# R7FA2A1AB register map
Vendor: Renesas; Series: RA2; File version: 1.1
CPU: CM23 r1p0, little endian, MPU, no FPU, VTOR, 2 interrupt priority bits
Registers are 8-bit, read-write, reset 0x0 unless marked. A register's access mark holds for its fields unless they carry their own. Offsets are from the block's base; [hi:lo] are bit positions; {n}, {i} and the like mark numbered series.

## SYSTEM — System Control
Base 0x4001E000
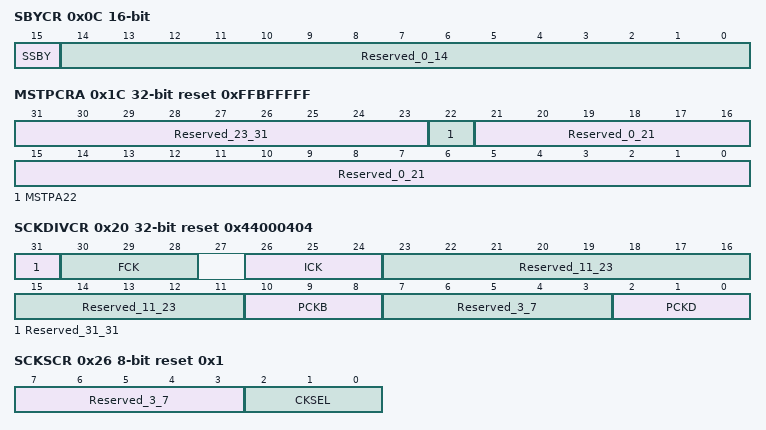
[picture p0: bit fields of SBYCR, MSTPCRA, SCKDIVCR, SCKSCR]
0x0C SBYCR 16-bit — Standby Control Register
  [15] SSBY — Software Standby
  [14:0] Reserved_0_14 — These bits are read as 000000000000000. The write value should be 000000000000000.
0x1C MSTPCRA 32-bit reset 0xFFBFFFFF — Module Stop Control Register A
  [31:23] Reserved_23_31 — These bits are read as 111111111. The write value should be 111111111.
  [22] MSTPA22 — Data Transfer Controller Module Stop
  [21:0] Reserved_0_21 — These bits are read as 1111111111111111111111. The write value should be 1111111111111111111111.
0x20 SCKDIVCR 32-bit reset 0x44000404 — System Clock Division Control Register
  [31] Reserved_31_31 — This bit is read as 0. The write value should be 0.
  [30:28] FCK — Flash IF Clock (FCLK) Select
  [26:24] ICK — System Clock (ICLK) Select
  [23:11] Reserved_11_23 — These bits are read as 0000000000000. The write value should be 0000000000000.
  [10:8] PCKB — Peripheral Module Clock B (PCLKB) Select
  [7:3] Reserved_3_7 — These bits are read as 00000. The write value should be 00000.
  [2:0] PCKD — Peripheral Module Clock D (PCLKD) Select
0x26 SCKSCR reset 0x1 — System Clock Source Control Register
  [7:3] Reserved_3_7 — These bits are read as 00000. The write value should be 00000.
  [2:0] CKSEL — Clock Source Select
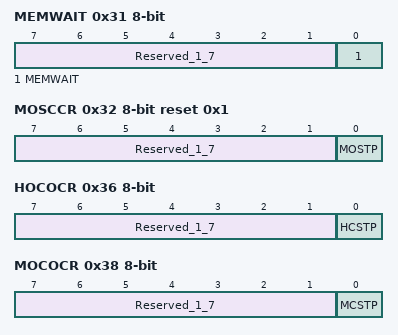
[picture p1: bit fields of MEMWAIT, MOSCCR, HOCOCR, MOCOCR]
0x31 MEMWAIT — Memory Wait Cycle Control Register
  [7:1] Reserved_1_7 — These bits are read as 0000000. The write value should be 0000000.
  [0] MEMWAIT — Memory Wait Cycle Select
0x32 MOSCCR reset 0x1 — Main Clock Oscillator Control Register
  [7:1] Reserved_1_7 — These bits are read as 0000000. The write value should be 0000000.
  [0] MOSTP — Main Clock Oscillator Stop
0x36 HOCOCR (reset mask 0xFE) — High,Speed On,Chip Oscillator Control Register
  [7:1] Reserved_1_7 — These bits are read as 0000000. The write value should be 0000000.
  [0] HCSTP — HOCO Stop
0x38 MOCOCR — Middle,Speed On,Chip Oscillator Control Register
  [7:1] Reserved_1_7 — These bits are read as 0000000. The write value should be 0000000.
  [0] MCSTP — MOCO Stop
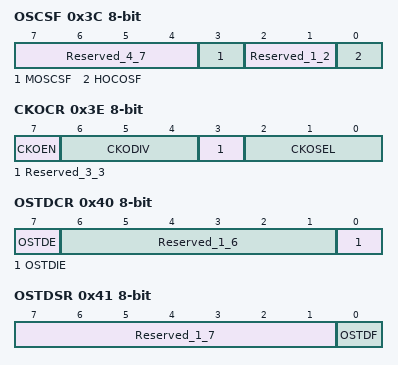
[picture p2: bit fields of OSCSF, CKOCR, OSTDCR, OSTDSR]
0x3C OSCSF ro (reset mask 0xFE) — Oscillation Stabilization Flag Register
  [7:4] Reserved_4_7 — These bits are read as 0000.
  [3] MOSCSF — Main Clock Oscillation Stabilization Flag
  [2:1] Reserved_1_2 — These bits are read as 00.
  [0] HOCOSF — HOCO Clock Oscillation Stabilization FlagNOTE: The HOCOSF bit value after a reset is 1 when the OFS1.HOCOEN bit is 0. It is 0 when the OFS1.HOCOEN bit is 1.
0x3E CKOCR — Clock Out Control Register
  [7] CKOEN — Clock out enable
  [6:4] CKODIV — Clock out input frequency Division Select
  [3] Reserved_3_3 — This bit is read as 0. The write value should be 0.
  [2:0] CKOSEL — Clock out source select
0x40 OSTDCR — Oscillation Stop Detection Control Register
  [7] OSTDE — Oscillation Stop Detection Function Enable
  [6:1] Reserved_1_6 — These bits are read as 000000. The write value should be 000000.
  [0] OSTDIE — Oscillation Stop Detection Interrupt Enable
0x41 OSTDSR — Oscillation Stop Detection Status Register
  [7:1] Reserved_1_7 — These bits are read as 0000000. The write value should be 0000000.
  [0] OSTDF write-0-clears read-modifies — Oscillation Stop Detection Flag
0x61 MOCOUTCR — MOCO User Trimming Control Register
  [7:0] MOCOUTRM — MOCO User Trimming 1000_0000 : -128 1000_0001 : -127 1000_0010 : -126 . . . 1111_1111 : -1 0000_0000 : Center Code 0000_0001 : +1 . . . 0111_1101 : +125 0111_1110 : +126 0111_1111 : +127These bits are added to original MOCO trimming bits
0x62 HOCOUTCR — HOCO User Trimming Control Register
  [7:0] HOCOUTRM — HOCO User Trimming 1000_0000 : -128 1000_0001 : -127 1000_0010 : -126 . . . 1111_1111 : -1 0000_0000 : Center Code 0000_0001 : +1 . . . 0111_1101 : +125 0111_1110 : +126 0111_1111 : +127These bits are added to original HOCO trimming bits
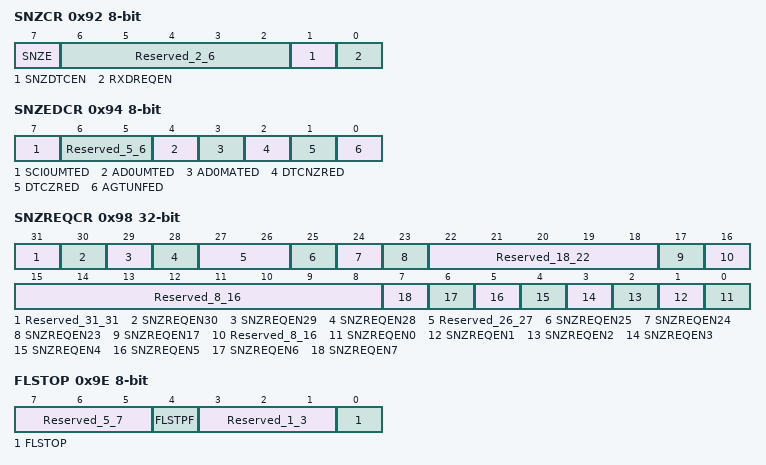
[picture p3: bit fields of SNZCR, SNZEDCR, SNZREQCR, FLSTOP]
0x92 SNZCR — Snooze Control Register
  [7] SNZE — Snooze Mode Enable
  [6:2] Reserved_2_6 — These bits are read as 00000. The write value should be 00000.
  [1] SNZDTCEN — DTC Enable in Snooze Mode
  [0] RXDREQEN — RXD0 Snooze Request Enable NOTE: Do not set to 1 other than in asynchronous mode.
0x94 SNZEDCR — Snooze End Control Register
  [7] SCI0UMTED — SCI0 address unmatch Snooze End EnableNote: Do not set to 1 other than in asynchronous mode.
  [6:5] Reserved_5_6 — These bits are read as 00. The write value should be 00.
  [4] AD0UMTED — AD compare mismatch 0 Snooze End Enable
  [3] AD0MATED — AD compare match 0 Snooze End Enable
  [2] DTCNZRED — Not Last DTC transmission completion Snooze End Enable
  [1] DTCZRED — Last DTC transmission completion Snooze End Enable
  [0] AGTUNFED — AGT1 underflow Snooze End Enable
0x98 SNZREQCR 32-bit — Snooze Request Control Register
  [31] Reserved_31_31 — This bit is read as 0. The write value should be 0.
  [30] SNZREQEN30 — Snooze Request Enable 30Enable AGT1 compare match B snooze request
  [29] SNZREQEN29 — Snooze Request Enable 29Enable AGT1 compare match A snooze request
  [28] SNZREQEN28 — Snooze Request Enable 28Enable AGT1 underflow snooze request
  [27:26] Reserved_26_27 — These bits are read as 00. The write value should be 00.
  [25] SNZREQEN25 — Snooze Request Enable 25Enable RTC period snooze request
  [24] SNZREQEN24 — Snooze Request Enable 24Enable RTC alarm snooze request
  [23] SNZREQEN23 — Snooze Request Enable 24Enable RTC alarm snooze request
  [22:18] Reserved_18_22 — These bits are read as 00000. The write value should be 00000.
  [17] SNZREQEN17 — Snooze Request Enable 17Enable KINT snooze request
  [16:8] Reserved_8_16 — These bits are read as 000000000. The write value should be 000000000.
  [n] SNZREQEN{n} (n=0..7) — Snooze Request Enable {n}Enable IRQ{n} pin snooze request
0x9E FLSTOP — Flash Operation Control Register
  [7:5] Reserved_5_7 — These bits are read as 000. The write value should be 000.
  [4] FLSTPF ro — Flash Memory Operation Status Flag
  [3:1] Reserved_1_3 — These bits are read as 000. The write value should be 000.
  [0] FLSTOP — Selecting ON/OFF of the Flash Memory Operation
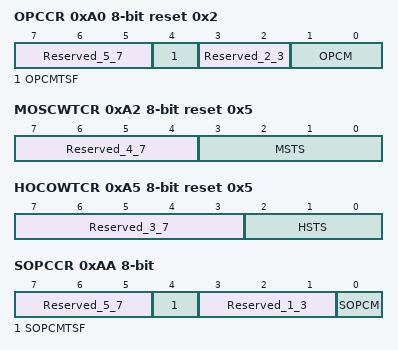
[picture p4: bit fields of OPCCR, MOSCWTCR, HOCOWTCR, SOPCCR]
0xA0 OPCCR reset 0x2 — Operating Power Control Register
  [7:5] Reserved_5_7 — These bits are read as 000. The write value should be 000.
  [4] OPCMTSF ro — Operating Power Control Mode Transition Status Flag
  [3:2] Reserved_2_3 — These bits are read as 00. The write value should be 00.
  [1:0] OPCM — Operating Power Control Mode Select
0xA2 MOSCWTCR reset 0x5 — Main Clock Oscillator Wait Control Register
  [7:4] Reserved_4_7 — These bits are read as 0000. The write value should be 0000.
  [3:0] MSTS — Main clock oscillator wait time setting
0xA5 HOCOWTCR reset 0x5 — High,Speed On,Chip Oscillator Wait Control Register
  [7:3] Reserved_3_7 — These bits are read as 00000. The write value should be 00000.
  [2:0] HSTS — HOCO wait time setting
0xAA SOPCCR — Sub Operating Power Control Register
  [7:5] Reserved_5_7 — These bits are read as 000. The write value should be 000.
  [4] SOPCMTSF ro — Sub Operating Power Control Mode Transition Status Flag
  [3:1] Reserved_1_3 — These bits are read as 000. The write value should be 000.
  [0] SOPCM — Sub Operating Power Control Mode Select
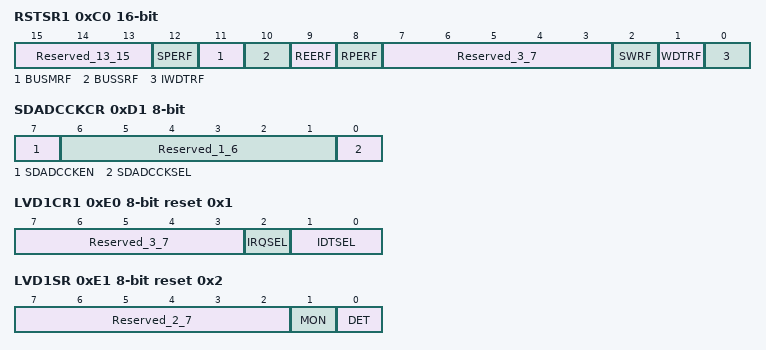
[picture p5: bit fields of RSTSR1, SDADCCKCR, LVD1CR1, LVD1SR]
0xC0 RSTSR1 16-bit (reset mask 0xE0F8) — Reset Status Register 1
  [15:13] Reserved_13_15 — These bits are read as 000. The write value should be 000.
  [12] SPERF write-0-clears read-modifies — SP Error Reset Detect FlagNote: Only 0 can be written to clear the flag. The reset flag must be written as 0 after the reset flag is read as 1.
  [11] BUSMRF write-0-clears read-modifies — Bus Master MPU Reset Detect FlagNote: Only 0 can be written to clear the flag. The reset flag must be written as 0 after the reset flag is read as 1.
  [10] BUSSRF write-0-clears read-modifies — Bus Slave MPU Reset Detect FlagNote: Only 0 can be written to clear the flag. The reset flag must be written as 0 after the reset flag is read as 1.
  [9] REERF write-0-clears read-modifies — RAM ECC Error Reset Detect FlagNote: Only 0 can be written to clear the flag. The reset flag must be written as 0 after the reset flag is read as 1.
  [8] RPERF write-0-clears read-modifies — RAM Parity Error Reset Detect FlagNote: Only 0 can be written to clear the flag. The reset flag must be written as 0 after the reset flag is read as 1.
  [7:3] Reserved_3_7 — These bits are read as 00000. The write value should be 00000.
  [2] SWRF write-0-clears read-modifies — Software Reset Detect FlagNote: Only 0 can be written to clear the flag. The reset flag must be written as 0 after the reset flag is read as 1.
  [1] WDTRF write-0-clears read-modifies — Watchdog Timer Reset Detect FlagNote: Only 0 can be written to clear the flag. The reset flag must be written as 0 after the reset flag is read as 1.
  [0] IWDTRF write-0-clears read-modifies — Independent Watchdog Timer Reset Detect FlagNote: Only 0 can be written to clear the flag. The reset flag must be written as 0 after the reset flag is read as 1.
0xD1 SDADCCKCR — 24-bit Sigma,Delta A/D Converter Clock Control Register
  [7] SDADCCKEN — 24-bit Sigma,Delta A/D Converter Clock Select
  [6:1] Reserved_1_6 — These bits are read as 000000. The write value should be 000000.
  [0] SDADCCKSEL — 24-bit Sigma,Delta A/D Converter Clock Enable
0xE0 LVD1CR1 reset 0x1 — Voltage Monitor 1 Circuit Control Register 1
  [7:3] Reserved_3_7 — These bits are read as 00000. The write value should be 00000.
  [2] IRQSEL — Voltage Monitor 1 Interrupt Type Select
  [1:0] IDTSEL — Voltage Monitor 1 Interrupt Generation Condition Select
0xE1 LVD1SR reset 0x2 — Voltage Monitor 1 Circuit Status Register
  [7:2] Reserved_2_7 — These bits are read as 000000. The write value should be 000000.
  [1] MON ro — Voltage Monitor 1 Signal Monitor Flag
  [0] DET write-0-clears read-modifies — Voltage Monitor 1 Voltage Change Detection Flag
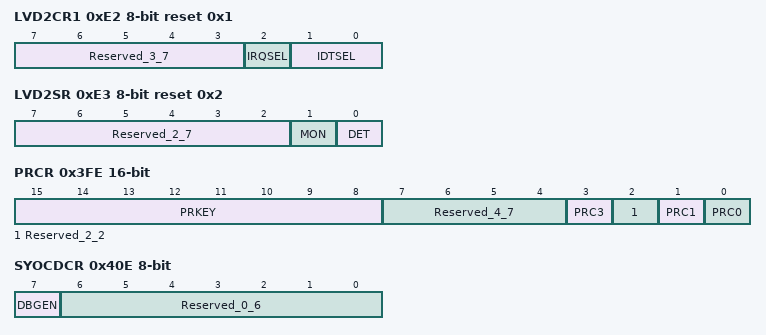
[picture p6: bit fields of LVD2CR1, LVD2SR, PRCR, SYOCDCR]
0xE2 LVD2CR1 reset 0x1 — Voltage Monitor 2 Circuit Control Register 1
  [7:3] Reserved_3_7 — These bits are read as 00000. The write value should be 00000.
  [2] IRQSEL — Voltage Monitor 2 Interrupt Type Select
  [1:0] IDTSEL — Voltage Monitor 2 Interrupt Generation Condition Select
0xE3 LVD2SR reset 0x2 — Voltage Monitor 2 Circuit Status Register
  [7:2] Reserved_2_7 — These bits are read as 000000. The write value should be 000000.
  [1] MON ro — Voltage Monitor 2 Signal Monitor Flag
  [0] DET write-0-clears read-modifies — Voltage Monitor 2 Voltage Change Detection Flag
0x3FE PRCR 16-bit — Protect Register
  [15:8] PRKEY wo — PRKEY Key Code
  [7:4] Reserved_4_7 — These bits are read as 0000. The write value should be 0000.
  [3] PRC3 — Enables writing to the registers related to the LVD.
  [2] Reserved_2_2 — This bit is read as 0. The write value should be 0.
  [1] PRC1 — Enables writing to the registers related to the operating modes, the low power consumption modes and the battery backup function.
  [0] PRC0 — Enables writing to the registers related to the clock generation circuit.
0x40E SYOCDCR — System Control OCD Control Register
  [7] DBGEN write-0-clears read-modifies — Debugger Enable
  [6:0] Reserved_0_6 — These bits are read as 0000000. The write value should be 0000000.
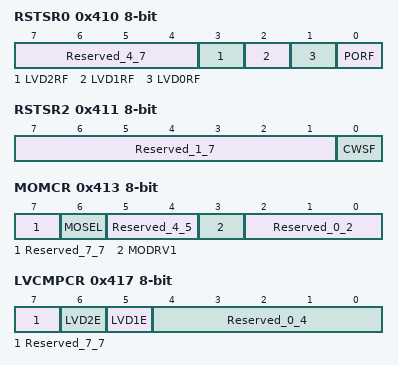
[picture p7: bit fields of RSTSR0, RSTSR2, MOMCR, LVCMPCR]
0x410 RSTSR0 (reset mask 0xF0) — Reset Status Register 0
  [7:4] Reserved_4_7 — These bits are read as 0000. The write value should be 0000.
  [3] LVD2RF write-0-clears read-modifies — Voltage Monitor 2 Reset Detect FlagNote: Only 0 can be written to clear the flag. The reset flag must be written with 0 after the reset flag is read as 1.
  [2] LVD1RF write-0-clears read-modifies — Voltage Monitor 1 Reset Detect FlagNote: Only 0 can be written to clear the flag. The reset flag must be written with 0 after the reset flag is read as 1.
  [1] LVD0RF write-0-clears read-modifies — Voltage Monitor 0 Reset Detect FlagNote: Only 0 can be written to clear the flag. The reset flag must be written with 0 after the reset flag is read as 1.
  [0] PORF write-0-clears read-modifies — Power,On Reset Detect FlagNote: Only 0 can be written to clear the flag. The reset flag must be written with 0 after the reset flag is read as 1.
0x411 RSTSR2 (reset mask 0xFE) — Reset Status Register 2
  [7:1] Reserved_1_7 — These bits are read as 0000000. The write value should be 0000000.
  [0] CWSF write-1-sets read-modifies — Cold/Warm Start Determination FlagNote: Only 1 can be written to set the flag.
0x413 MOMCR — Main Clock Oscillator Mode Oscillation Control Register
  [7] Reserved_7_7 — This bit is read as 0. The write value should be 0.
  [6] MOSEL — Main Clock Oscillator Switching
  [5:4] Reserved_4_5 — These bits are read as 00. The write value should be 00.
  [3] MODRV1 — Main Clock Oscillator Drive Capability 1 Switching
  [2:0] Reserved_0_2 — These bits are read as 000. The write value should be 000.
0x417 LVCMPCR — Voltage Monitor Circuit Control Register
  [7] Reserved_7_7 — This bit is read as 0. The write value should be 0.
  [6] LVD2E — Voltage Detection 2 Enable
  [5] LVD1E — Voltage Detection 1 Enable
  [4:0] Reserved_0_4 — These bits are read as 00000. The write value should be 00000.
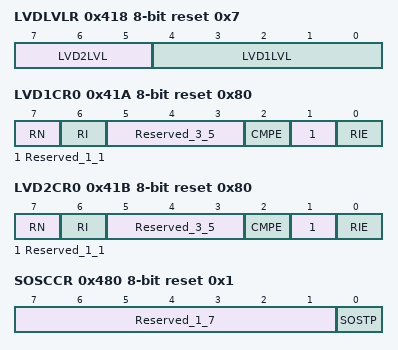
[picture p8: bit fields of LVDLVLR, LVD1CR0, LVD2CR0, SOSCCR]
0x418 LVDLVLR reset 0x7 — Voltage Detection Level Select Register
  [7:5] LVD2LVL — Voltage Detection 2 Level Select (Standard voltage during drop in voltage)
  [4:0] LVD1LVL — Voltage Detection 1 Level Select (Standard voltage during drop in voltage)
0x41A LVD1CR0 reset 0x80 (reset mask 0xF7) — Voltage Monitor 1 Circuit Control Register 0
  [7] RN — Voltage Monitor 1 Reset Negate Select
  [6] RI — Voltage Monitor 1 Circuit Mode Select
  [5:3] Reserved_3_5 — These bits are read as 000. The write value should be 000.
  [2] CMPE — Voltage Monitor 1 Circuit Comparison Result Output Enable
  [1] Reserved_1_1 — This bit is read as 0. The write value should be 0.
  [0] RIE — Voltage Monitor 1 Interrupt/ Reset Enable
0x41B LVD2CR0 reset 0x80 (reset mask 0xF7) — Voltage Monitor 2 Circuit Control Register 0
  [7] RN — Voltage Monitor 2 Reset Negate Select
  [6] RI — Voltage Monitor 2 Circuit Mode Select
  [5:3] Reserved_3_5 — These bits are read as 000. The write value should be 000.
  [2] CMPE — Voltage Monitor 2 Circuit Comparison Result Output Enable
  [1] Reserved_1_1 — This bit is read as 0. The write value should be 0.
  [0] RIE — Voltage Monitor 2 Interrupt/Reset Enable
0x480 SOSCCR reset 0x1 — Sub,clock Oscillator Control Register
  [7:1] Reserved_1_7 — These bits are read as 0000000. The write value should be 0000000.
  [0] SOSTP — Sub,Clock Oscillator Stop
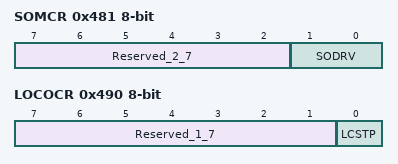
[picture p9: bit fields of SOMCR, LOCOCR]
0x481 SOMCR — Sub,clock Oscillator Mode Control Register
  [7:2] Reserved_2_7 — These bits are read as 000000. The write value should be 000000.
  [1:0] SODRV — Sub Clock Oscillator Drive Capability Switching
0x490 LOCOCR — Low,Speed On,Chip Oscillator Control Register
  [7:1] Reserved_1_7 — These bits are read as 0000000. The write value should be 0000000.
  [0] LCSTP — LOCO Stop
0x492 LOCOUTCR — LOCO User Trimming Control Register
  [7:0] LOCOUTRM — LOCO User Trimming 1000_0000 : -128 1000_0001 : -127 1000_0010 : -126 . . . 1111_1111 : -1 0000_0000 : Center Code 0000_0001 : +1 . . . 0111_1101 : +125 0111_1110 : +126 0111_1111 : +127These bits are added to original LOCO trimming bits
